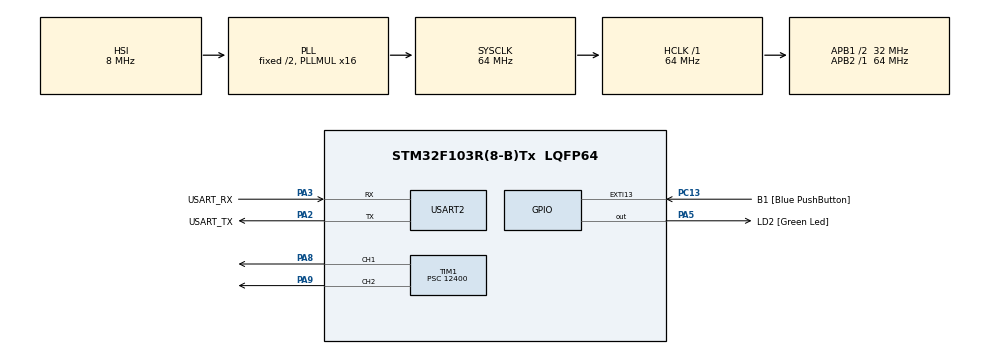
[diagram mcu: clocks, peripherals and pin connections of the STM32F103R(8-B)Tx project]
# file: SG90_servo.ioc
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Mcu.Family=STM32F1
PC15-OSC32_OUT.Mode=LSE-External-Oscillator
PA2.GPIO_PuPd=GPIO_NOPULL
PD1-OSC_OUT.Mode=HSE-External-Clock-Source
PA14.GPIO_Label=TCK
PA3.GPIO_PuPd=GPIO_NOPULL
PA2.GPIO_Speed=GPIO_SPEED_FREQ_LOW
PC13-TAMPER-RTC.Signal=GPXTI13
PD0-OSC_IN.Signal=RCC_OSC_IN
TIM1.Pulse-PWM\ Generation1\ CH1=20
RCC.APB1CLKDivider=RCC_HCLK_DIV2
PC14-OSC32_IN.Signal=RCC_OSC32_IN
PA3.GPIO_Speed=GPIO_SPEED_FREQ_LOW
RCC.SYSCLKSource=RCC_SYSCLKSOURCE_PLLCLK
ProjectManager.StackSize=0x400
PD1-OSC_OUT.Signal=RCC_OSC_OUT
PA13.Signal=SYS_JTMS-SWDIO
PA3.Mode=Asynchronous
TIM1.OC1Preload_PWM=DISABLE
TIM1.Prescaler=12400
SH.S_TIM1_CH1.0=TIM1_CH1,PWM Generation1 CH1
ProjectManager.TargetToolchain=STM32CubeIDE
PA3.GPIO_Mode=GPIO_MODE_AF_PP
RCC.HCLKFreq_Value=64000000
RCC.APB2TimFreq_Value=64000000
PA9.Signal=S_TIM1_CH2
TIM1.Channel-PWM\ Generation2\ CH2=TIM_CHANNEL_2
RCC.USBFreq_Value=64000000
PC15-OSC32_OUT.Signal=RCC_OSC32_OUT
RCC.AHBFreq_Value=64000000
PD0-OSC_IN.Mode=HSE-External-Clock-Source
NVIC.EXTI15_10_IRQn=true\:0\:0\:false\:false\:true\:true\:true
PA5.Signal=GPIO_Output
board=NUCLEO-F103RB
RCC.RTCClockSelection=RCC_RTCCLKSOURCE_LSE
PC13-TAMPER-RTC.GPIO_Label=B1 [Blue PushButton]
RCC.PLLMUL=RCC_PLL_MUL16
RCC.APB2Freq_Value=64000000
PC14-OSC32_IN.Mode=LSE-External-Oscillator
PA5.GPIO_ModeDefaultOutputPP=GPIO_MODE_OUTPUT_PP
SH.S_TIM1_CH2.0=TIM1_CH2,PWM Generation2 CH2
TIM1.Channel-PWM\ Generation1\ CH1=TIM_CHANNEL_1
PA14.Mode=Serial_Wire
PA5.GPIO_PuPd=GPIO_NOPULL
PA8.Signal=S_TIM1_CH1
PA13.Mode=Serial_Wire
Mcu.Name=STM32F103R(8-B)Tx
VP_TIM1_VS_ClockSourceINT.Mode=Internal
PA2.Signal=USART2_TX
PA13.GPIO_Label=TMS
PB3.Signal=SYS_JTDO-TRACESWO
RCC.SYSCLKFreq_VALUE=64000000
Mcu.Package=LQFP64
PA5.GPIO_Label=LD2 [Green Led]
USART2.VirtualMode=VM_ASYNC
PC13-TAMPER-RTC.GPIO_PuPd=GPIO_NOPULL
PA2.GPIO_Label=USART_TX
PA14.Signal=SYS_JTCK-SWCLK
ProjectManager.HeapSize=0x200
PA5.GPIO_Speed=GPIO_SPEED_FREQ_LOW
NVIC.PriorityGroup=NVIC_PRIORITYGROUP_4
RCC.APB1TimFreq_Value=64000000
PA2.Mode=Asynchronous
TIM1.Period=100
RCC.APB1Freq_Value=32000000
PA3.GPIO_Label=USART_RX
PA3.Signal=USART2_RX
PA2.GPIO_Mode=GPIO_MODE_AF_PP
PB3.GPIO_Label=SWO

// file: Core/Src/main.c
/* USER CODE BEGIN Header */
/**
  ******************************************************************************
  * @file           : main.c
  * @brief          : Main program body
  ******************************************************************************
  * @attention
  *
  * <h2><center>&copy; Copyright (c) 2021 STMicroelectronics.
  * All rights reserved.</center></h2>
  *
  * This software component is licensed by ST under BSD 3-Clause license,
  * the "License"; You may not use this file except in compliance with the
  * License. You may obtain a copy of the License at:
  *                        opensource.org/licenses/BSD-3-Clause
  *
  ******************************************************************************
  */
/* USER CODE END Header */
#include "main.h"
#include "tim.h"
#include "usart.h"
#include "gpio.h"

/* USER CODE BEGIN Includes */
#include "sg90.h"
/* USER CODE END Includes */

/* USER CODE BEGIN PTD */
servo_motor sg90_servo;
servo_motor sg90_servo2;
/* USER CODE END PTD */

void SystemClock_Config(void);

int main(void)
{

  /* MCU Configuration--------------------------------------------------------*/

  /* Reset of all peripherals, Initializes the Flash interface and the Systick. */
  HAL_Init();

  /* Configure the system clock */
  SystemClock_Config();

  /* Initialize all configured peripherals */
  MX_GPIO_Init();
  MX_USART2_UART_Init();
  MX_TIM1_Init();
  /* USER CODE BEGIN 2 */
  sg90_init(&sg90_servo, &htim1, TIM_CHANNEL_1);
  sg90_init(&sg90_servo2, &htim1, TIM_CHANNEL_2);
  /* USER CODE END 2 */

  /* Infinite loop */
  /* USER CODE BEGIN WHILE */
  while (1)
  {
	  for(int i=0; i<180; i+=10)
	  {
		  sg90_set_angle(&sg90_servo, i);
		  sg90_set_angle(&sg90_servo2, i);
		  HAL_Delay(1000);
	  }

    /* USER CODE END WHILE */

  }
}

void SystemClock_Config(void)
{
  RCC_OscInitTypeDef RCC_OscInitStruct = {0};
  RCC_ClkInitTypeDef RCC_ClkInitStruct = {0};

  /** Initializes the RCC Oscillators according to the specified parameters
  * in the RCC_OscInitTypeDef structure.
  */
  RCC_OscInitStruct.OscillatorType = RCC_OSCILLATORTYPE_HSI;
  RCC_OscInitStruct.HSIState = RCC_HSI_ON;
  RCC_OscInitStruct.HSICalibrationValue = RCC_HSICALIBRATION_DEFAULT;
  RCC_OscInitStruct.PLL.PLLState = RCC_PLL_ON;
  RCC_OscInitStruct.PLL.PLLSource = RCC_PLLSOURCE_HSI_DIV2;
  RCC_OscInitStruct.PLL.PLLMUL = RCC_PLL_MUL16;
  if (HAL_RCC_OscConfig(&RCC_OscInitStruct) != HAL_OK)
  {
    Error_Handler();
  }
  /** Initializes the CPU, AHB and APB buses clocks
  */
  RCC_ClkInitStruct.ClockType = RCC_CLOCKTYPE_HCLK|RCC_CLOCKTYPE_SYSCLK
                              |RCC_CLOCKTYPE_PCLK1|RCC_CLOCKTYPE_PCLK2;
  RCC_ClkInitStruct.SYSCLKSource = RCC_SYSCLKSOURCE_PLLCLK;
  RCC_ClkInitStruct.AHBCLKDivider = RCC_SYSCLK_DIV1;
  RCC_ClkInitStruct.APB1CLKDivider = RCC_HCLK_DIV2;
  RCC_ClkInitStruct.APB2CLKDivider = RCC_HCLK_DIV1;

  if (HAL_RCC_ClockConfig(&RCC_ClkInitStruct, FLASH_LATENCY_2) != HAL_OK)
  {
    Error_Handler();
  }
}

void Error_Handler(void)
{
  __disable_irq();
  while (1)
  {
  }
}

/************************ (C) COPYRIGHT STMicroelectronics *****END OF FILE****/
